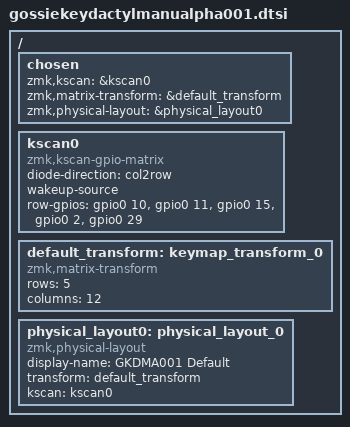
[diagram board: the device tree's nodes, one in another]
#include <dt-bindings/zmk/matrix_transform.h>

/ {
    chosen {
        zmk,kscan = &kscan0;
        zmk,matrix-transform = &default_transform;
        zmk,physical-layout = &physical_layout0;
    };

    kscan0: kscan0 {
        compatible = "zmk,kscan-gpio-matrix";
        diode-direction = "col2row";
        wakeup-source;

        row-gpios
            = <&gpio0 10 (GPIO_ACTIVE_HIGH | GPIO_PULL_DOWN)>,
              <&gpio0 11 (GPIO_ACTIVE_HIGH | GPIO_PULL_DOWN)>,
              <&gpio0 15 (GPIO_ACTIVE_HIGH | GPIO_PULL_DOWN)>,
              <&gpio0 2  (GPIO_ACTIVE_HIGH | GPIO_PULL_DOWN)>,
              <&gpio0 29 (GPIO_ACTIVE_HIGH | GPIO_PULL_DOWN)>;
    };

    default_transform: keymap_transform_0 {
        compatible = "zmk,matrix-transform";
        rows = <5>;
        columns = <12>;
    };

    physical_layout0: physical_layout_0 {
        compatible = "zmk,physical-layout";
        display-name = "GKDMA001 Default";
    };
};

&physical_layout0 {
    transform = <&default_transform>;
    kscan = <&kscan0>;
};
